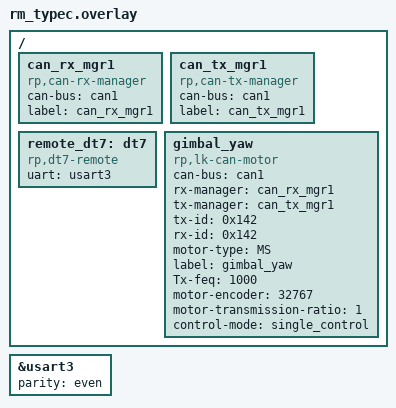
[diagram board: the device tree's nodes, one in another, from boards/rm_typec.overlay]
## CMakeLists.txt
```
cmake_minimum_required(VERSION 3.20)

if(NOT BOARD)
    set(BOARD rm_typec)
endif()

set(DTC_OVERLAY_FILE "${CMAKE_CURRENT_LIST_DIR}/boards/rm_typec.overlay"
	CACHE STRING "Devicetree overlay for the down application" FORCE)

list(APPEND ZEPHYR_EXTRA_MODULES
    "${WEST_TOPDIR}/breeze-modules"
    "${WEST_TOPDIR}/lob-hero/common"
)

find_package(Zephyr REQUIRED HINTS $ENV{ZEPHYR_BASE})

project(lob-hero-down)

file(GLOB_RECURSE APP_SOURCES CONFIGURE_DEPNDS
	"${CMAKE_CURRENT_LIST_DIR}/src/*.cpp"
)

target_sources(app
	PRIVATE
		${APP_SOURCES}
)

target_include_directories(app
	PRIVATE
		"${CMAKE_CURRENT_LIST_DIR}/inc"
)

target_link_libraries(app
	PRIVATE
		lob_hero::interface
		lob_hero::sensors
		lob_hero::motors
		lob_hero::models
		lob_hero::b2b
		breeze::module::b2b
		breeze::module::gimbal
		breeze::module::models
)
```

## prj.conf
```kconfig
CONFIG_BREEZE=y
CONFIG_CPP=y
CONFIG_STD_CPP20=y
CONFIG_RAMENX=y
CONFIG_GLIBCXX_LIBCPP=y
CONFIG_REQUIRES_FULL_LIBCPP=y
CONFIG_LOG=y
CONFIG_NO_OPTIMIZATIONS=y
CONFIG_THREAD_NAME=y

CONFIG_REMOTE=y
CONFIG_REMOTE_PROTOCOL_DT7=y
CONFIG_UART_ASYNC_API=y
CONFIG_RP_UART_STM32=y
CONFIG_UART_STM32=y

CONFIG_CAN=y
CONFIG_ISOTP=y

CONFIG_BREEZE=y
CONFIG_BREEZE_MODULES=y
CONFIG_BREEZE_MODULE_GIMBAL=y
CONFIG_ALGO=y
CONFIG_CAN_RX_MANAGER=y
CONFIG_CAN_TX_MANAGER=y
CONFIG_BLDCM=y
```

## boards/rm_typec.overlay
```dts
/* DT7 receiver on the rm_typec USART3 RX pin (PC11). */

&usart3 {
	parity = "even";
};

/ {
    can_rx_mgr1: can_rx_mgr1 {
        compatible = "rp,can-rx-manager";
        status = "okay";
        can-bus = <&can1>;
        label = "can_rx_mgr1";
    };

    can_tx_mgr1: can_tx_mgr1 {
        compatible = "rp,can-tx-manager";
        status = "okay";
        can-bus = <&can1>;
        label = "can_tx_mgr1";
    };

	remote_dt7: dt7 {
		compatible = "rp,dt7-remote";
		status = "okay";
		uart = <&usart3>;
	};

	gimbal_yaw: gimbal_yaw {
		compatible = "rp,lk-can-motor";
		status = "okay";
		can-bus = <&can1>;
		rx-manager = <&can_rx_mgr1>;
		tx-manager = <&can_tx_mgr1>;
		tx-id = <0x142>;
		rx-id = <0x142>;
		motor-type = "MS";
		label = "gimbal_yaw";
		Tx-feq = <1000>;
		motor-encoder = <32767>;
		motor-transmission-ratio = <1>; // TODO: 找具体减速比
		control-mode = "single_control";
	};
};
```

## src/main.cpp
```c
/**
 * @file main.cpp
 * @author vix_hentx (w1084349470@outlook.com)
 * @brief Lob Hero Down Board 的应用层主入口
 * @version 0.1
 * @date 2026-11-21
 *
 * @copyright Copyright (c) 2026
 *
 */

#include <app/b2b/module.hpp>
#include <app/models/device.hpp>
#include <app/models/priority.hpp>
#include <app/motors/module.hpp>
#include <app/sensors/rc.hpp>
#include <breeze/gimbal/yaw1_pitch1_pid.hpp>
#include <ramenx/time.hpp>
#include <zephyr/device.h>
#include <zephyr/devicetree.h>
#include <zephyr/kernel.h>

namespace app
{

ramen::FrameProvider<512> controlFrame{
    {.period = K_MSEC(1), .priority = models::priority::CONTROL_TICK, .name = "control_tick"}
};
b2b::DownModule b2bCom{DEVICE_DT_GET(DT_NODELABEL(can1))};
sensors::RC rc{DEVICE_DT_GET(DT_NODELABEL(remote_dt7))};
breeze::gimbal::Yaw1Pitch1PidModule gimbal{{}};
motors::LkModule gimbalYawMotor{
    DEVICE_DT_GET(DT_NODELABEL(gimbal_yaw)),
    {.EncoderCounts = DT_PROP(DT_NODELABEL(gimbal_yaw), motor_encoder),
	 .TransmissionRatio = DT_PROP(DT_NODELABEL(gimbal_yaw), motor_transmission_ratio),
	 .IqCommandPerNewtonMeter = 1.4f}
};

static void Start()
{
	controlFrame.start();
	gimbal.Start();
	//
}

static void Connect()
{
	// Tick wire
	controlFrame.out >> rc.InTick;
	controlFrame.out >> gimbalYawMotor.InTick;

	// Data wire

	gimbal.InHeadImu >> b2bCom.Out.Imus[models::ImuId::Head];
	gimbal.OutPitchMotor >> b2bCom.In.Motors[models::MotorId::HeadPitch];
	gimbal.OutYawMotor >> gimbalYawMotor.InControl;

	rc.OutPosture >> gimbal.InMachTarget;
	//
}

} // namespace app

int main()
{
	app::Connect();
	app::Start();
}
```
